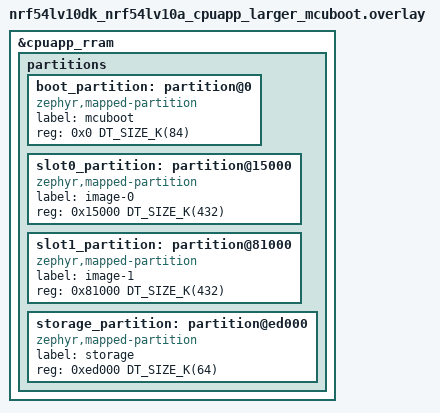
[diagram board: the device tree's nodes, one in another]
/*
 * Copyright (c) 2026 Nordic Semiconductor ASA
 *
 * SPDX-License-Identifier: LicenseRef-Nordic-5-Clause
 */

/delete-node/ &boot_partition;
/delete-node/ &slot0_partition;
/delete-node/ &slot1_partition;
/delete-node/ &storage_partition;

&cpuapp_rram {
	partitions {
		boot_partition: partition@0 {
			compatible = "zephyr,mapped-partition";
			label = "mcuboot";
			reg = <0x0 DT_SIZE_K(84)>;
		};

		slot0_partition: partition@15000 {
			compatible = "zephyr,mapped-partition";
			label = "image-0";
			reg = <0x15000 DT_SIZE_K(432)>;
		};

		slot1_partition: partition@81000 {
			compatible = "zephyr,mapped-partition";
			label = "image-1";
			reg = <0x81000 DT_SIZE_K(432)>;
		};

		storage_partition: partition@ed000 {
			compatible = "zephyr,mapped-partition";
			label = "storage";
			reg = <0xed000 DT_SIZE_K(64)>;
		};
	};
};
